# TC37XPD register map
Vendor: Infineon; Series: ATVMC; File version: 100
CPU: other r0p0, little endian, MPU, FPU, vendor SysTick, 4 interrupt priority bits
Registers are 32-bit, read-write, reset 0x0 unless marked. A register's access mark holds for its fields unless they carry their own. Offsets are from the block's base; [hi:lo] are bit positions; {n}, {i} and the like mark numbered series.

## GETH (part 4 of 7)
Base 0xF001D000
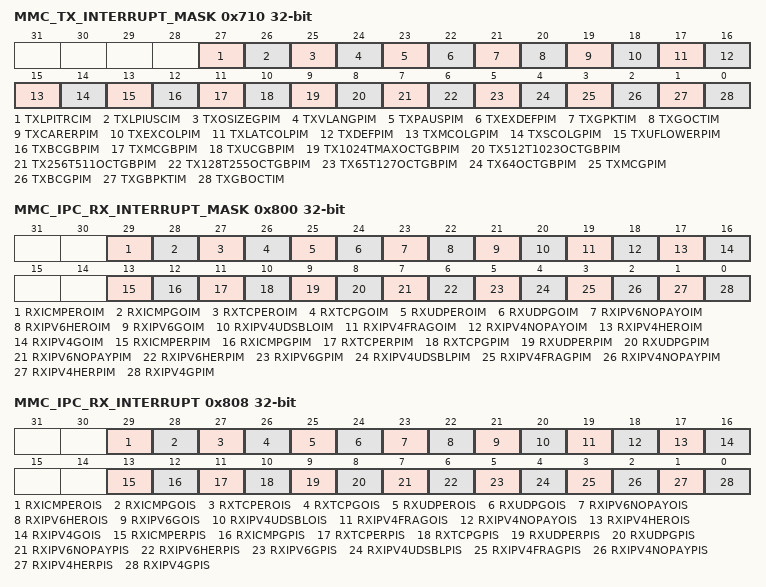
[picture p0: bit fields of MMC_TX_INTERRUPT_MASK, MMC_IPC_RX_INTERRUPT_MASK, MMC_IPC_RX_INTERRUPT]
0x710 MMC_TX_INTERRUPT_MASK — MMC Transmit Interrupts Mask Register resetvalue={Application Reset:0x0}
  [27] TXLPITRCIM — MMC Transmit LPI transition counter interrupt Mask TXLPITRCIM. Setting this bit masks the interrupt when the Tx LPI Tran Cntr counter reaches half of the maximum value or the maximum value. Value After Reset 0x0
  [26] TXLPIUSCIM — MMC Transmit LPI microsecond counter interrupt Mask TXLPIUSCIM. Setting this bit masks the interrupt when the Tx LPI USEC Cntr counter reaches half of the maximum value or the maximum value. Value After Reset 0x0
  [25] TXOSIZEGPIM — MMC Transmit Oversize Good Packet Counter Interrupt Mask TXOSIZEGPIM. Setting this bit masks the interrupt when the txoversize g counter reaches half of the maximum value or the maximum value. Value After Reset 0x0
  [24] TXVLANGPIM — MMC Transmit VLAN Good Packet Counter Interrupt Mask TXVLANGPIM. Setting this bit masks the interrupt when the txvlanpackets g counter reaches half of the maximum value or the maximum value. Value After Reset 0x0
  [23] TXPAUSPIM — MMC Transmit Pause Packet Counter Interrupt Mask TXPAUSPIM. Setting this bit masks the interrupt when the txpausepackets counter reaches half of the maximum value or the maximum value. Value After Reset 0x0
  [22] TXEXDEFPIM — MMC Transmit Excessive Deferral Packet Counter Interrupt Mask TXEXDEFPIM. Setting this bit masks the interrupt when the txexcessdef counter reaches half of the maximum value or the maximum value. Value After Reset 0x0
  [21] TXGPKTIM — MMC Transmit Good Packet Counter Interrupt Mask TXGPKTIM. Setting this bit masks the interrupt when the txpacketcount g counter reaches half of the maximum value or the maximum value. Value After Reset 0x0
  [20] TXGOCTIM — MMC Transmit Good Octet Counter Interrupt Mask TXGOCTIM. Setting this bit masks the interrupt when the txoctetcount g counter reaches half of the maximum value or the maximum value. Value After Reset 0x0
  [19] TXCARERPIM — MMC Transmit Carrier Error Packet Counter Interrupt Mask TXCARERPIM. Setting this bit masks the interrupt when the txcarriererror counter reaches half of the maximum value or the maximum value. Value After Reset 0x0
  [18] TXEXCOLPIM — MMC Transmit Excessive Collision Packet Counter Interrupt Mask TXEXCOLPIM. Setting this bit masks the interrupt when the txexcesscol counter reaches half of the maximum value or the maximum value. Value After Reset 0x0
  [17] TXLATCOLPIM — MMC Transmit Late Collision Packet Counter Interrupt Mask TXLATCOLPIM. Setting this bit masks the interrupt when the txlatecol counter reaches half of the maximum value or the maximum value. Value After Reset 0x0
  [16] TXDEFPIM — MMC Transmit Deferred Packet Counter Interrupt Mask TXDEFPIM. Setting this bit masks the interrupt when the txdeferred counter reaches half of the maximum value or the maximum value. Value After Reset 0x0
  [15] TXMCOLGPIM — MMC Transmit Multiple Collision Good Packet Counter Interrupt Mask TXMCOLGPIM. Setting this bit masks the interrupt when the txmulticol g counter reaches half of the maximum value or the maximum value. Value After Reset 0x0
  [14] TXSCOLGPIM — MMC Transmit Single Collision Good Packet Counter Interrupt Mask TXSCOLGPIM. Setting this bit masks the interrupt when the txsinglecol g counter reaches half of the maximum value or the maximum value. Value After Reset 0x0
  [13] TXUFLOWERPIM — MMC Transmit Underflow Error Packet Counter Interrupt Mask TXUFLOWERPIM. Setting this bit masks the interrupt when the txunderflowerror counter reaches half of the maximum value or the maximum value. Value After Reset 0x0
  [12] TXBCGBPIM — MMC Transmit Broadcast Good Bad Packet Counter Interrupt Mask TXBCGBPIM. Setting this bit masks the interrupt when the txbroadcastpackets gb counter reaches half of the maximum value or the maximum value. Value After Reset 0x0
  [11] TXMCGBPIM — MMC Transmit Multicast Good Bad Packet Counter Interrupt Mask TXMCGBPIM. Setting this bit masks the interrupt when the txmulticastpackets gb counter reaches half of the maximum value or the maximum value. Value After Reset 0x0
  [10] TXUCGBPIM — MMC Transmit Unicast Good Bad Packet Counter Interrupt Mask TXUCGBPIM. Setting this bit masks the interrupt when the txunicastpackets gb counter reaches half of the maximum value or the maximum value. Value After Reset 0x0
  [9] TX1024TMAXOCTGBPIM — MMC Transmit 1024 to Maximum Octet Good Bad Packet Counter Interrupt Mask TX1024TMAXOCTGBPIM. Setting this bit masks the interrupt when the tx1024tomaxoctets gb counter reaches half of the maximum value or the maximum value. Value After Reset 0x0
  [8] TX512T1023OCTGBPIM — MMC Transmit 512 to 1023 Octet Good Bad Packet Counter Interrupt Mask TX512T1023OCTGBPIM. Setting this bit masks the interrupt when the tx512to1023octets gb counter reaches half of the maximum value or the maximum value. Value After Reset 0x0
  [7] TX256T511OCTGBPIM — MMC Transmit 256 to 511 Octet Good Bad Packet Counter Interrupt Mask TX256T511OCTGBPIM. Setting this bit masks the interrupt when the tx256to511octets gb counter reaches half of the maximum value or the maximum value. Value After Reset 0x0
  [6] TX128T255OCTGBPIM — MMC Transmit 128 to 255 Octet Good Bad Packet Counter Interrupt Mask TX128T255OCTGBPIM. Setting this bit masks the interrupt when the tx128to255octets gb counter reaches half of the maximum value or the maximum value. Value After Reset 0x0
  [5] TX65T127OCTGBPIM — MMC Transmit 65 to 127 Octet Good Bad Packet Counter Interrupt Mask TX65T127OCTGBPIM. Setting this bit masks the interrupt when the tx65to127octets gb counter reaches half of the maximum value or the maximum value. Value After Reset 0x0
  [4] TX64OCTGBPIM — MMC Transmit 64 Octet Good Bad Packet Counter Interrupt Mask TX64OCTGBPIM. Setting this bit masks the interrupt when the tx64octets gb counter reaches half of the maximum value or the maximum value. Value After Reset 0x0
  [3] TXMCGPIM — MMC Transmit Multicast Good Packet Counter Interrupt Mask TXMCGPIM. Setting this bit masks the interrupt when the txmulticastpackets g counter reaches half of the maximum value or the maximum value. Value After Reset 0x0
  [2] TXBCGPIM — MMC Transmit Broadcast Good Packet Counter Interrupt Mask TXBCGPIM. Setting this bit masks the interrupt when the txbroadcastpackets g counter reaches half of the maximum value or the maximum value. Value After Reset 0x0
  [1] TXGBPKTIM — MMC Transmit Good Bad Packet Counter Interrupt Mask TXGBPKTIM. Setting this bit masks the interrupt when the txpacketcount gb counter reaches half of the maximum value or the maximum value. Value After Reset 0x0
  [0] TXGBOCTIM — MMC Transmit Good Bad Octet Counter Interrupt Mask TXGBOCTIM. Setting this bit masks the interrupt when the txoctetcount gb counter reaches half of the maximum value or the maximum value. Value After Reset 0x0
0x714 TX_OCTET_COUNT_GOOD_BAD ro — Good And Bad Transmitted Octet Count Register resetvalue={Application Reset:0x0}
  [31:0] TXOCTGB — Tx Octet Count Good Bad TXOCTGB. This field indicates the number of bytes transmitted exclusive of preamble and retried bytes in good and bad packets. Value After Reset 0x0
0x718 TX_PACKET_COUNT_GOOD_BAD ro — Good And Bad Transmitted Packets Count Register resetvalue={Application Reset:0x0}
  [15:0] TXPKTGB — Tx Packet Count Good Bad TXPKTGB. This field indicates the number of good and bad packets transmitted exclusive of retried packets. Value After Reset 0x0
0x71C TX_BROADCAST_PACKETS_GOOD ro — Good Transmitted Broadcast Packets Count Register resetvalue={Application Reset:0x0}
  [15:0] TXBCASTG — Tx Broadcast Packets Good TXBCASTG. This field indicates the number of good broadcast packets transmitted. Value After Reset 0x0
0x720 TX_MULTICAST_PACKETS_GOOD ro — Good Transmitted Multicast Packets Count Register resetvalue={Application Reset:0x0}
  [15:0] TXMCASTG — Tx Multicast Packets Good TXMCASTG. This field indicates the number of good multicast packets transmitted. Value After Reset 0x0
0x724 TX_64OCTETS_PACKETS_GOOD_BAD ro — Good And Bad 64 Octets Packets Transmitted Count Register resetvalue={Application Reset:0x0}
  [15:0] TX64OCTGB — Tx 64Octets Packets Good Bad TX64OCTGB. This field indicates the number of good and bad packets transmitted with length 64 bytes exclusive of preamble and retried packets. Value After Reset 0x0
0x728 TX_65TO127OCTETS_PACKETS_GOOD_BAD ro — Good And Bad 65to127 Octets Packets Transmitted Count Register resetvalue={Application Reset:0x0}
  [15:0] TX65_127OCTGB — Tx 65To127Octets Packets Good Bad TX65 127OCTGB. This field indicates the number of good and bad packets transmitted with length between 65 and 127 inclusive bytes exclusive of preamble and retried packets. Value After Reset 0x0
0x72C TX_128TO255OCTETS_PACKETS_GOOD_BAD ro — Good And Bad 128to255 Octets Packets Transmitted Count Register resetvalue={Application Reset:0x0}
  [15:0] TX128_255OCTGB — Tx 128To255Octets Packets Good Bad TX128 255OCTGB. This field indicates the number of good and bad packets transmitted with length between 128 and 255 inclusive bytes exclusive of preamble and retried packets. Value After Reset 0x0
0x730 TX_256TO511OCTETS_PACKETS_GOOD_BAD ro — Good And Bad 256to511 Octets Packets Transmitted Count Register resetvalue={Application Reset:0x0}
  [15:0] TX256_511OCTGB — Tx 256To511Octets Packets Good Bad TX256 511OCTGB. This field indicates the number of good and bad packets transmitted with length between 256 and 511 inclusive bytes exclusive of preamble and retried packets. Value After Reset 0x0
0x734 TX_512TO1023OCTETS_PACKETS_GOOD_BAD ro — Good And Bad 512to1023 Octets Packets Transmitted Count Register resetvalue={Application Reset:0x0}
  [15:0] TX512_1023OCTGB — Tx 512To1023Octets Packets Good Bad TX512 1023OCTGB. This field indicates the number of good and bad packets transmitted with length between 512 and 1023 inclusive bytes exclusive of preamble and retried packets. Value After Reset 0x0
0x738 TX_1024TOMAXOCTETS_PACKETS_GOOD_BAD ro — Good And Bad 1024toMax Octets Packets Transmitted Count Register resetvalue={Application Reset:0x0}
  [15:0] TX1024_MAXOCTGB — Tx 1024ToMaxOctets Packets Good Bad TX1024 MAXOCTGB. This field indicates the number of good and bad packets transmitted with length between 1024 and maxsize inclusive bytes exclusive of preamble and retried packets. Value After Reset 0x0
0x73C TX_UNICAST_PACKETS_GOOD_BAD ro — Good Transmitted Unicat Packets Count Register resetvalue={Application Reset:0x0}
  [15:0] TXUCASTGB — Tx Unicast Packets Good Bad TXUCASTGB. This field indicates the number of good and bad unicast packets transmitted. Value After Reset 0x0
0x740 TX_MULTICAST_PACKETS_GOOD_BAD ro — Good And Bad Transmitted Multicast Packets Count Register resetvalue={Application Reset:0x0}
  [15:0] TXMCASTGB — Tx Multicast Packets Good Bad TXMCASTGB. This field indicates the number of good and bad multicast packets transmitted. Value After Reset 0x0
0x744 TX_BROADCAST_PACKETS_GOOD_BAD ro — Good And Bad Transmitted Broadcast Packets Count Register resetvalue={Application Reset:0x0}
  [15:0] TXBCASTGB — Tx Broadcast Packets Good Bad TXBCASTGB. This field indicates the number of good and bad broadcast packets transmitted. Value After Reset 0x0
0x748 TX_UNDERFLOW_ERROR_PACKETS ro — Transmitted Underflow Error Packets Count Register resetvalue={Application Reset:0x0}
  [15:0] TXUNDRFLW — Tx Underflow Error Packets TXUNDRFLW. This field indicates the number of packets aborted because of packets underflow error. Value After Reset 0x0
0x74C TX_SINGLE_COLLISION_GOOD_PACKETS ro — Good Transmitted Single Collision Count Register resetvalue={Application Reset:0x0}
  [15:0] TXSNGLCOLG — Tx Single Collision Good Packets TXSNGLCOLG. This field indicates the number of successfully transmitted packets after a single collision in the half duplex mode. Value After Reset 0x0
0x750 TX_MULTIPLE_COLLISION_GOOD_PACKETS ro — Transmitted Multiple Collision Count Register resetvalue={Application Reset:0x0}
  [15:0] TXMULTCOLG — Tx Multiple Collision Good Packets TXMULTCOLG. This field indicates the number of successfully transmitted packets after multiple collisions in the half duplex mode. Value After Reset 0x0
0x754 TX_DEFERRED_PACKETS ro — Transmitted Deferred Packets Count Register resetvalue={Application Reset:0x0}
  [15:0] TXDEFRD — Tx Deferred Packets TXDEFRD. This field indicates the number of successfully transmitted after a deferral in the half duplex mode. Value After Reset 0x0
0x758 TX_LATE_COLLISION_PACKETS ro — Transmitted Late Collision Packets Count Register resetvalue={Application Reset:0x0}
  [15:0] TXLATECOL — Tx Late Collision Packets TXLATECOL. This field indicates the number of packets aborted because of late collision error. Value After Reset 0x0
0x75C TX_EXCESSIVE_COLLISION_PACKETS ro — Transmitted Excessive Collision Packets Count Register resetvalue={Application Reset:0x0}
  [15:0] TXEXSCOL — Tx Excessive Collision Packets TXEXSCOL. This field indicates the number of packets aborted because of excessive 16 collision errors. Value After Reset 0x0
0x760 TX_CARRIER_ERROR_PACKETS ro — Transmitted Carrier Error Packets Count Register resetvalue={Application Reset:0x0}
  [15:0] TXCARR — Tx Carrier Error Packets TXCARR. This field indicates the number of packets aborted because of carrier sense error no carrier or loss of carrier . Value After Reset 0x0
0x764 TX_OCTET_COUNT_GOOD ro — Good Transmitted Octet Count Register resetvalue={Application Reset:0x0}
  [31:0] TXOCTG — Tx Octet Count Good TXOCTG. This field indicates the number of bytes transmitted exclusive of preamble only in good packets. Value After Reset 0x0
0x768 TX_PACKET_COUNT_GOOD ro — Good Transmitted Packet Count Register resetvalue={Application Reset:0x0}
  [15:0] TXPKTG — Tx Packet Count Good TXPKTG. This field indicates the number of good packets transmitted. Value After Reset 0x0
0x76C TX_EXCESSIVE_DEFERRAL_ERROR ro — Transmitted Excessive Deferral Error Count Register resetvalue={Application Reset:0x0}
  [15:0] TXEXSDEF — Tx Excessive Deferral Error TXEXSDEF. This field indicates the number of packets aborted because of excessive deferral error deferred for more than two max sized packet times . Value After Reset 0x0
0x770 TX_PAUSE_PACKETS ro — Transmitted Pause Packets Count Register resetvalue={Application Reset:0x0}
  [15:0] TXPAUSE — Tx Pause Packets TXPAUSE. This field indicates the number of good Pause packets transmitted. Value After Reset 0x0
0x774 TX_VLAN_PACKETS_GOOD ro — Good Transmitted VLAN Packets Count Register resetvalue={Application Reset:0x0}
  [15:0] TXVLANG — Tx VLAN Packets Good TXVLANG. This field provides the number of good VLAN packets transmitted. Value After Reset 0x0
0x778 TX_OSIZE_PACKETS_GOOD ro — Good Transmitted Osize Packets Count Register resetvalue={Application Reset:0x0}
  [15:0] TXOSIZG — Tx OSize Packets Good TXOSIZG. This field indicates the number of packets transmitted without errors and with length greater than the maxsize 1 518 or 1 522 bytes for VLAN tagged packets 2000 bytes if enabled in S2KP bit of the MAC Configuration register . Value After Reset 0x0
0x780 RX_PACKETS_COUNT_GOOD_BAD ro — Good And Bad Received Packets Count Register resetvalue={Application Reset:0x0}
  [15:0] RXPKTGB — Rx Packets Count Good Bad RXPKTGB. This field indicates the number of good and bad packets received. Value After Reset 0x0
0x784 RX_OCTET_COUNT_GOOD_BAD ro — Good And Bad Received Octet Count Register resetvalue={Application Reset:0x0}
  [31:0] RXOCTGB — Rx Octet Count Good Bad RXOCTGB. This field indicates the number of bytes received exclusive of preamble in good and bad packets. Value After Reset 0x0
0x788 RX_OCTET_COUNT_GOOD ro — Good Received Octet Count Register resetvalue={Application Reset:0x0}
  [31:0] RXOCTG — Rx Octet Count Good RXOCTG. This field indicates the number of bytes received exclusive of preamble only in good packets. Value After Reset 0x0
0x78C RX_BROADCAST_PACKETS_GOOD ro — Good Received Broadcast Packets Count Register resetvalue={Application Reset:0x0}
  [15:0] RXBCASTG — Rx Broadcast Packets Good RXBCASTG. This field indicates the number of good broadcast packets received. Value After Reset 0x0
0x790 RX_MULTICAST_PACKETS_GOOD ro — Good Received Multicast Packets Count Register resetvalue={Application Reset:0x0}
  [15:0] RXMCASTG — Rx Multicast Packets Good RXMCASTG. This field indicates the number of good multicast packets received. Value After Reset 0x0
0x794 RX_CRC_ERROR_PACKETS ro — Received CRC Error Packets Count Register resetvalue={Application Reset:0x0}
  [15:0] RXCRCERR — Rx CRC Error Packets RXCRCERR. This field indicates the number of packets received with CRC error. Value After Reset 0x0
0x798 RX_ALIGNMENT_ERROR_PACKETS ro — Received Alignment Error Count Register resetvalue={Application Reset:0x0}
  [15:0] RXALGNERR — Rx Alignment Error Packets RXALGNERR. This field indicates the number of packets received with alignment dribble error. It is valid only in 10 100 mode. Value After Reset 0x0
0x79C RX_RUNT_ERROR_PACKETS ro — Received Runtime Error Count Register resetvalue={Application Reset:0x0}
  [15:0] RXRUNTERR — Rx Runt Error Packets RXRUNTERR. This field indicates the number of packets received with runt length less than 64 bytes and CRC error error. Value After Reset 0x0
0x7A0 RX_JABBER_ERROR_PACKETS ro — Received Jabber Error Count Register resetvalue={Application Reset:0x0}
  [15:0] RXJABERR — Rx Jabber Error Packets RXJABERR. This field indicates the number of giant packets received with length including CRC greater than 1 518 bytes 1 522 bytes for VLAN tagged and with CRC error. If Jumbo Packet mode is enabled packets of length greater than 9 018 bytes 9 022 bytes for VLAN tagged are considered as giant packets. Value After Reset 0x0
0x7A4 RX_UNDERSIZE_PACKETS_GOOD ro — Good Received Undersized Packets Count Register resetvalue={Application Reset:0x0}
  [15:0] RXUNDERSZG — Rx Undersize Packets Good RXUNDERSZG. This field indicates the number of packets received with length less than 64 bytes without any errors. Value After Reset 0x0
0x7A8 RX_OVERSIZE_PACKETS_GOOD ro — Good Received Oversized Packets Count Register resetvalue={Application Reset:0x0}
  [15:0] RXOVERSZG — Rx Oversize Packets Good RXOVERSZG. This field indicates the number of packets received without errors with length greater than the maxsize 1 518 bytes or 1 522 bytes for VLAN tagged packets 2000 bytes if enabled in the S2KP bit of the MAC Configuration register . Value After Reset 0x0
0x7AC RX_64OCTETS_PACKETS_GOOD_BAD ro — Good And Bad 64 Octets Packets Received Count Register resetvalue={Application Reset:0x0}
  [15:0] RX64OCTGB — Rx 64 Octets Packets Good Bad RX64OCTGB. This field indicates the number of good and bad packets received with length 64 bytes exclusive of the preamble. Value After Reset 0x0
0x7B0 RX_65TO127OCTETS_PACKETS_GOOD_BAD ro — Good And Bad 65to127 Octets Packets Received Count Register resetvalue={Application Reset:0x0}
  [15:0] RX65_127OCTGB — Rx 65 127 Octets Packets Good Bad RX65 127OCTGB. This field indicates the number of good and bad packets received with length between 65 and 127 inclusive bytes exclusive of the preamble. Value After Reset 0x0
0x7B4 RX_128TO255OCTETS_PACKETS_GOOD_BAD ro — Good And Bad 128to255 Octets Packets Received Count Register resetvalue={Application Reset:0x0}
  [15:0] RX128_255OCTGB — Rx 128 255 Octets Packets Good Bad RX128 255OCTGB. This field indicates the number of good and bad packets received with length between 128 and 255 inclusive bytes exclusive of the preamble. Value After Reset 0x0
0x7B8 RX_256TO511OCTETS_PACKETS_GOOD_BAD ro — Good And Bad 256to511 Octets Packets Received Count Register resetvalue={Application Reset:0x0}
  [15:0] RX256_511OCTGB — Rx 256 511 Octets Packets Good Bad RX256 511OCTGB. This field indicates the number of good and bad packets received with length between 256 and 511 inclusive bytes exclusive of the preamble. Value After Reset 0x0
0x7BC RX_512TO1023OCTETS_PACKETS_GOOD_BAD ro — Good And Bad 512to1023 Octets Packets Received Count Register resetvalue={Application Reset:0x0}
  [15:0] RX512_1023OCTGB — RX 512 1023 Octets Packets Good Bad RX512 1023OCTGB. This field indicates the number of good and bad packets received with length between 512 and 1023 inclusive bytes exclusive of the preamble. Value After Reset 0x0
0x7C0 RX_1024TOMAXOCTETS_PACKETS_GOOD_BAD ro — Good And Bad 1024toMax Octets Packets Received Count Register resetvalue={Application Reset:0x0}
  [15:0] RX1024_MAXOCTGB — Rx 1024 Max Octets Good Bad RX1024 MAXOCTGB. This field indicates the number of good and bad packets received with length between 1024 and maxsize inclusive bytes exclusive of the preamble. Value After Reset 0x0
0x7C4 RX_UNICAST_PACKETS_GOOD ro — Good Received Unicat Packets Count Register resetvalue={Application Reset:0x0}
  [15:0] RXUCASTG — Rx Unicast Packets Good RXUCASTG. This field indicates the number of good unicast packets received. Value After Reset 0x0
0x7C8 RX_LENGTH_ERROR_PACKETS ro — Received Length Error Packets Count Register resetvalue={Application Reset:0x0}
  [15:0] RXLENERR — Rx Length Error Packets RXLENERR. This field indicates the number of packets received with length error Length Type field not equal to packet size for all packets with valid length field. Value After Reset 0x0
0x7CC RX_OUT_OF_RANGE_TYPE_PACKETS ro — Received Out Of Range Type Count Register resetvalue={Application Reset:0x0}
  [15:0] RXOUTOFRNG — Rx Out of Range Type Packet RXOUTOFRNG. This field indicates the number of packets received with length field not equal to the valid packet size greater than 1 500 but less than 1 536 . Value After Reset 0x0
0x7D0 RX_PAUSE_PACKETS ro — Received Pause Packets Count Register resetvalue={Application Reset:0x0}
  [15:0] RXPAUSEPKT — Rx Pause Packets RXPAUSEPKT. This field indicates the number of good and valid Pause packets received. Value After Reset 0x0
0x7D4 RX_FIFO_OVERFLOW_PACKETS ro — Received FIFO Overflow Count Register resetvalue={Application Reset:0x0}
  [15:0] RXFIFOOVFL — Rx FIFO Overflow Packets RXFIFOOVFL. This field indicates the number of missed received packets because of FIFO overflow. Value After Reset 0x0
0x7D8 RX_VLAN_PACKETS_GOOD_BAD ro — Good And Bad Received VLAN Packets Count Registerv resetvalue={Application Reset:0x0}
  [15:0] RXVLANPKTGB — Rx VLAN Packets Good Bad RXVLANPKTGB. This field indicates the number of good and bad VLAN packets received. Value After Reset 0x0
0x7DC RX_WATCHDOG_ERROR_PACKETS ro — Received Watchdog Error Count Register resetvalue={Application Reset:0x0}
  [15:0] RXWDGERR — Rx Watchdog Error Packets RXWDGERR. This field indicates the number of packets received with error because of watchdog timeout error packets with a data load larger than 2 048 bytes when JE and WD bits are reset in MAC Configuration register 10 240 bytes when JE bit is set and WD bit is reset in MAC Configuration register 16 384 bytes when WD bit is set in MAC Configuration register or the value programmed in the MAC Watchdog Timeout register . Value After Reset 0x0
0x7E0 RX_RECEIVE_ERROR_PACKETS ro — Received Receive Error Count Register resetvalue={Application Reset:0x0}
  [15:0] RXRCVERR — Rx Receive Error Packets RXRCVERR. This field indicates the number of packets received with Receive error or Packet Extension error on the GMII or MII interface. Value After Reset 0x0
0x7E4 RX_CONTROL_PACKETS_GOOD ro — Good Received Control Packets Count Register resetvalue={Application Reset:0x0}
  [15:0] RXCTRLG — Rx Control Packets Good RXCTRLG. This field indicates the number of good control packets received. Value After Reset 0x0
0x7EC TX_LPI_USEC_CNTR ro — Transmitted LPI Microseconds Count Register resetvalue={Application Reset:0x0}
  [15:0] TXLPIUSC — Tx LPI Microseconds Counter TXLPIUSC. This field indicates the number of microseconds Tx LPI is asserted. For every Tx LPI Entry and Exit the Timer value can have an error of 1 microsecond. Value After Reset 0x0
0x7F0 TX_LPI_TRAN_CNTR ro — Transmitted LPI Transition Count Register resetvalue={Application Reset:0x0}
  [15:0] TXLPITRC — Tx LPI Transition counter TXLPITRC. This field indicates the number of times Tx LPI Entry has occurred. Even if Tx LPI Entry occurs in Automate Mode because of LPITXA bit set in the LPI Control and Status register the counter will increment. Value After Reset 0x0
0x7F4 RX_LPI_USEC_CNTR ro — Received Microseconds LPI Count Register resetvalue={Application Reset:0x0}
  [15:0] RXLPIUSC — Rx LPI Microseconds Counter RXLPIUSC. This field indicates the number of microseconds Rx LPI is asserted. For every Rx LPI Entry and Exit the Timer value can have an error of 1 microsecond. Value After Reset 0x0
0x7F8 RX_LPI_TRAN_CNTR ro — Received LPI Transition Count Register resetvalue={Application Reset:0x0}
  [15:0] RXLPITRC — Rx LPI Transition counter RXLPITRC. This field indicates the number of times Rx LPI Entry has occurred. Value After Reset 0x0
0x800 MMC_IPC_RX_INTERRUPT_MASK — MMC IPC Receive Interrupts Mask Register resetvalue={Application Reset:0x0}
  [29] RXICMPEROIM — MMC Receive ICMP Error Octet Counter Interrupt Mask RXICMPEROIM. Setting this bit masks the interrupt when the rxicmp err octets counter reaches half of the maximum value or the maximum value. Value After Reset 0x0
  [28] RXICMPGOIM — MMC Receive ICMP Good Octet Counter Interrupt Mask RXICMPGOIM. Setting this bit masks the interrupt when the rxicmp gd octets counter reaches half of the maximum value or the maximum value. Value After Reset 0x0
  [27] RXTCPEROIM — MMC Receive TCP Error Octet Counter Interrupt Mask RXTCPEROIM. Setting this bit masks the interrupt when the rxtcp err octets counter reaches half of the maximum value or the maximum value. Value After Reset 0x0
  [26] RXTCPGOIM — MMC Receive TCP Good Octet Counter Interrupt Mask RXTCPGOIM. Setting this bit masks the interrupt when the rxtcp gd octets counter reaches half of the maximum value or the maximum value. Value After Reset 0x0
  [25] RXUDPEROIM — MMC Receive UDP Good Octet Counter Interrupt Mask RXUDPEROIM. Setting this bit masks the interrupt when the rxudp err octets counter reaches half of the maximum value or the maximum value. Value After Reset 0x0
  [24] RXUDPGOIM — MMC Receive IPV6 No Payload Octet Counter Interrupt Mask RXUDPGOIM. Setting this bit masks the interrupt when the rxudp gd octets counter reaches half of the maximum value or the maximum value. Value After Reset 0x0
  [23] RXIPV6NOPAYOIM — MMC Receive IPV6 Header Error Octet Counter Interrupt Mask RXIPV6NOPAYOIM. Setting this bit masks the interrupt when the rxipv6 nopay octets counter reaches half of the maximum value or the maximum value. Value After Reset 0x0
  [22] RXIPV6HEROIM — MMC Receive IPV6 Good Octet Counter Interrupt Mask RXIPV6HEROIM. Setting this bit masks the interrupt when the rxipv6 hdrerr octets counter reaches half of the maximum value or the maximum value. Value After Reset 0x0
  [21] RXIPV6GOIM — MMC Receive IPV6 Good Octet Counter Interrupt Mask RXIPV6GOIM. Setting this bit masks the interrupt when the rxipv6 gd octets counter reaches half of the maximum value or the maximum value. Value After Reset 0x0
  [20] RXIPV4UDSBLOIM — MMC Receive IPV4 UDP Checksum Disabled Octet Counter Interrupt Mask RXIPV4UDSBLOIM. Setting this bit masks the interrupt when the rxipv4 udsbl octets counter reaches half of the maximum value or the maximum value. Value After Reset 0x0
  [19] RXIPV4FRAGOIM — MMC Receive IPV4 Fragmented Octet Counter Interrupt Mask RXIPV4FRAGOIM. Setting this bit masks the interrupt when the rxipv4 frag octets counter reaches half of the maximum value or the maximum value. Value After Reset 0x0
  [18] RXIPV4NOPAYOIM — MMC Receive IPV4 No Payload Octet Counter Interrupt Mask RXIPV4NOPAYOIM. Setting this bit masks the interrupt when the rxipv4 nopay octets counter reaches half of the maximum value or the maximum value. Value After Reset 0x0
  [17] RXIPV4HEROIM — MMC Receive IPV4 Header Error Octet Counter Interrupt Mask RXIPV4HEROIM. Setting this bit masks the interrupt when the rxipv4 hdrerr octets counter reaches half of the maximum value or the maximum value. Value After Reset 0x0
  [16] RXIPV4GOIM — MMC Receive IPV4 Good Octet Counter Interrupt Mask RXIPV4GOIM. Setting this bit masks the interrupt when the rxipv4 gd octets counter reaches half of the maximum value or the maximum value. Value After Reset 0x0
  [13] RXICMPERPIM — MMC Receive ICMP Error Packet Counter Interrupt Mask RXICMPERPIM. Setting this bit masks the interrupt when the rxicmp err pkts counter reaches half of the maximum value or the maximum value. Value After Reset 0x0
  [12] RXICMPGPIM — MMC Receive ICMP Good Packet Counter Interrupt Mask RXICMPGPIM. Setting this bit masks the interrupt when the rxicmp gd pkts counter reaches half of the maximum value or the maximum value. Value After Reset 0x0
  [11] RXTCPERPIM — MMC Receive TCP Error Packet Counter Interrupt Mask RXTCPERPIM. Setting this bit masks the interrupt when the rxtcp err pkts counter reaches half of the maximum value or the maximum value. Value After Reset 0x0
  [10] RXTCPGPIM — MMC Receive TCP Good Packet Counter Interrupt Mask RXTCPGPIM. Setting this bit masks the interrupt when the rxtcp gd pkts counter reaches half of the maximum value or the maximum value. Value After Reset 0x0
  [9] RXUDPERPIM — MMC Receive UDP Error Packet Counter Interrupt Mask RXUDPERPIM. Setting this bit masks the interrupt when the rxudp err pkts counter reaches half of the maximum value or the maximum value. Value After Reset 0x0
  [8] RXUDPGPIM — MMC Receive UDP Good Packet Counter Interrupt Mask RXUDPGPIM. Setting this bit masks the interrupt when the rxudp gd pkts counter reaches half of the maximum value or the maximum value. Value After Reset 0x0
  [7] RXIPV6NOPAYPIM — MMC Receive IPV6 No Payload Packet Counter Interrupt Mask RXIPV6NOPAYPIM. Setting this bit masks the interrupt when the rxipv6 nopay pkts counter reaches half of the maximum value or the maximum value. Value After Reset 0x0
  [6] RXIPV6HERPIM — MMC Receive IPV6 Header Error Packet Counter Interrupt Mask RXIPV6HERPIM. Setting this bit masks the interrupt when the rxipv6 hdrerr pkts counter reaches half of the maximum value or the maximum value. Value After Reset 0x0
  [5] RXIPV6GPIM — MMC Receive IPV6 Good Packet Counter Interrupt Mask RXIPV6GPIM. Setting this bit masks the interrupt when the rxipv6 gd pkts counter reaches half of the maximum value or the maximum value. Value After Reset 0x0
  [4] RXIPV4UDSBLPIM — MMC Receive IPV4 UDP Checksum Disabled Packet Counter Interrupt Mask RXIPV4UDSBLPIM. Setting this bit masks the interrupt when the rxipv4 udsbl pkts counter reaches half of the maximum value or the maximum value. Value After Reset 0x0
  [3] RXIPV4FRAGPIM — MMC Receive IPV4 Fragmented Packet Counter Interrupt Mask RXIPV4FRAGPIM. Setting this bit masks the interrupt when the rxipv4 frag pkts counter reaches half of the maximum value or the maximum value. Value After Reset 0x0
  [2] RXIPV4NOPAYPIM — MMC Receive IPV4 No Payload Packet Counter Interrupt Mask RXIPV4NOPAYPIM. Setting this bit masks the interrupt when the rxipv4 nopay pkts counter reaches half of the maximum value or the maximum value. Value After Reset 0x0
  [1] RXIPV4HERPIM — MMC Receive IPV4 Header Error Packet Counter Interrupt Mask RXIPV4HERPIM. Setting this bit masks the interrupt when the rxipv4 hdrerr pkts counter reaches half of the maximum value or the maximum value. Value After Reset 0x0
  [0] RXIPV4GPIM — MMC Receive IPV4 Good Packet Counter Interrupt Mask RXIPV4GPIM. Setting this bit masks the interrupt when the rxipv4 gd pkts counter reaches half of the maximum value or the maximum value. Value After Reset 0x0
0x808 MMC_IPC_RX_INTERRUPT ro — MMC IPC Receive Interrupts Register resetvalue={Application Reset:0x0}
  [29] RXICMPEROIS — MMC Receive ICMP Error Octet Counter Interrupt Status RXICMPEROIS. This bit is set when the rxicmp err octets counter reaches half of the maximum value or the maximum value. Access restriction applies. Clears on read. Self set to 1 on internal event. Value After Reset 0x0
  [28] RXICMPGOIS — MMC Receive ICMP Good Octet Counter Interrupt Status RXICMPGOIS. This bit is set when the rxicmp gd octets counter reaches half of the maximum value or the maximum value. Access restriction applies. Clears on read. Self set to 1 on internal event. Value After Reset 0x0
  [27] RXTCPEROIS — MMC Receive TCP Error Octet Counter Interrupt Status RXTCPEROIS. This bit is set when the rxtcp err octets counter reaches half of the maximum value or the maximum value. Access restriction applies. Clears on read. Self set to 1 on internal event. Value After Reset 0x0
  [26] RXTCPGOIS — MMC Receive TCP Good Octet Counter Interrupt Status RXTCPGOIS. This bit is set when the rxtcp gd octets counter reaches half of the maximum value or the maximum value. Access restriction applies. Clears on read. Self set to 1 on internal event. Value After Reset 0x0
  [25] RXUDPEROIS — MMC Receive UDP Error Octet Counter Interrupt Status RXUDPEROIS. This bit is set when the rxudp err octets counter reaches half of the maximum value or the maximum value. Access restriction applies. Clears on read. Self set to 1 on internal event. Value After Reset 0x0
  [24] RXUDPGOIS — MMC Receive UDP Good Octet Counter Interrupt Status RXUDPGOIS. This bit is set when the rxudp gd octets counter reaches half of the maximum value or the maximum value. Access restriction applies. Clears on read. Self set to 1 on internal event. Value After Reset 0x0
  [23] RXIPV6NOPAYOIS — MMC Receive IPV6 No Payload Octet Counter Interrupt Status RXIPV6NOPAYOIS. This bit is set when the rxipv6 nopay octets counter reaches half of the maximum value or the maximum value. Access restriction applies. Clears on read. Self set to 1 on internal event. Value After Reset 0x0
  [22] RXIPV6HEROIS — MMC Receive IPV6 Header Error Octet Counter Interrupt Status RXIPV6HEROIS. This bit is set when the rxipv6 hdrerr octets counter reaches half of the maximum value or the maximum value. Access restriction applies. Clears on read. Self set to 1 on internal event. Value After Reset 0x0
  [21] RXIPV6GOIS — MMC Receive IPV6 Good Octet Counter Interrupt Status RXIPV6GOIS. This bit is set when the rxipv6 gd octets counter reaches half of the maximum value or the maximum value. Access restriction applies. Clears on read. Self set to 1 on internal event. Value After Reset 0x0
  [20] RXIPV4UDSBLOIS — MMC Receive IPV4 UDP Checksum Disabled Octet Counter Interrupt Status RXIPV4UDSBLOIS. This bit is set when the rxipv4 udsbl octets counter reaches half of the maximum value or the maximum value. Access restriction applies. Clears on read. Self set to 1 on internal event. Value After Reset 0x0
  [19] RXIPV4FRAGOIS — MMC Receive IPV4 Fragmented Octet Counter Interrupt Status RXIPV4FRAGOIS. This bit is set when the rxipv4 frag octets counter reaches half of the maximum value or the maximum value. Access restriction applies. Clears on read. Self set to 1 on internal event. Value After Reset 0x0
  [18] RXIPV4NOPAYOIS — MMC Receive IPV4 No Payload Octet Counter Interrupt Status RXIPV4NOPAYOIS. This bit is set when the rxipv4 nopay octets counter reaches half of the maximum value or the maximum value. Access restriction applies. Clears on read. Self set to 1 on internal event. Value After Reset 0x0
  [17] RXIPV4HEROIS — MMC Receive IPV4 Header Error Octet Counter Interrupt Status RXIPV4HEROIS. This bit is set when the rxipv4 hdrerr octets counter reaches half of the maximum value or the maximum value. Access restriction applies. Clears on read. Self set to 1 on internal event. Value After Reset 0x0
  [16] RXIPV4GOIS — MMC Receive IPV4 Good Octet Counter Interrupt Status RXIPV4GOIS. This bit is set when the rxipv4 gd octets counter reaches half of the maximum value or the maximum value. Access restriction applies. Clears on read. Self set to 1 on internal event. Value After Reset 0x0
  [13] RXICMPERPIS — MMC Receive ICMP Error Packet Counter Interrupt Status RXICMPERPIS. This bit is set when the rxicmp err pkts counter reaches half of the maximum value or the maximum value. Access restriction applies. Clears on read. Self set to 1 on internal event. Value After Reset 0x0
  [12] RXICMPGPIS — MMC Receive ICMP Good Packet Counter Interrupt Status RXICMPGPIS. This bit is set when the rxicmp gd pkts counter reaches half of the maximum value or the maximum value. Access restriction applies. Clears on read. Self set to 1 on internal event. Value After Reset 0x0
  [11] RXTCPERPIS — MMC Receive TCP Error Packet Counter Interrupt Status RXTCPERPIS. This bit is set when the rxtcp err pkts counter reaches half of the maximum value or the maximum value. Access restriction applies. Clears on read. Self set to 1 on internal event. Value After Reset 0x0
  [10] RXTCPGPIS — MMC Receive TCP Good Packet Counter Interrupt Status RXTCPGPIS. This bit is set when the rxtcp gd pkts counter reaches half of the maximum value or the maximum value. Access restriction applies. Clears on read. Self set to 1 on internal event. Value After Reset 0x0
  [9] RXUDPERPIS — MMC Receive UDP Error Packet Counter Interrupt Status RXUDPERPIS. This bit is set when the rxudp err pkts counter reaches half of the maximum value or the maximum value. Access restriction applies. Clears on read. Self set to 1 on internal event. Value After Reset 0x0
  [8] RXUDPGPIS — MC Receive UDP Good Packet Counter Interrupt Status RXUDPGPIS. This bit is set when the rxudp gd pkts counter reaches half of the maximum value or the maximum value. Access restriction applies. Clears on read. Self set to 1 on internal event. Value After Reset 0x0
  [7] RXIPV6NOPAYPIS — MMC Receive IPV6 No Payload Packet Counter Interrupt Status RXIPV6NOPAYPIS. This bit is set when the rxipv6 nopay pkts counter reaches half of the maximum value or the maximum value. Access restriction applies. Clears on read. Self set to 1 on internal event. Value After Reset 0x0
  [6] RXIPV6HERPIS — MMC Receive IPV6 Header Error Packet Counter Interrupt Status RXIPV6HERPIS. This bit is set when the rxipv6 hdrerr pkts counter reaches half of the maximum value or the maximum value. Access restriction applies. Clears on read. Self set to 1 on internal event. Value After Reset 0x0
  [5] RXIPV6GPIS — MMC Receive IPV6 Good Packet Counter Interrupt Status RXIPV6GPIS. This bit is set when the rxipv6 gd pkts counter reaches half of the maximum value or the maximum value. Access restriction applies. Clears on read. Self set to 1 on internal event. Value After Reset 0x0
  [4] RXIPV4UDSBLPIS — MMC Receive IPV4 UDP Checksum Disabled Packet Counter Interrupt Status RXIPV4UDSBLPIS. This bit is set when the rxipv4 udsbl pkts counter reaches half of the maximum value or the maximum value. Value After Reset 0x0
  [3] RXIPV4FRAGPIS — MMC Receive IPV4 Fragmented Packet Counter Interrupt Status RXIPV4FRAGPIS. This bit is set when the rxipv4 frag pkts counter reaches half of the maximum value or the maximum value. Access restriction applies. Clears on read. Self set to 1 on internal event. Value After Reset 0x0
  [2] RXIPV4NOPAYPIS — MMC Receive IPV4 No Payload Packet Counter Interrupt Status RXIPV4NOPAYPIS. This bit is set when the rxipv4 nopay pkts counter reaches half of the maximum value or the maximum value. Access restriction applies. Clears on read. Self set to 1 on internal event. Value After Reset 0x0
  [1] RXIPV4HERPIS — MMC Receive IPV4 Header Error Packet Counter Interrupt Status RXIPV4HERPIS. This bit is set when the rxipv4 hdrerr pkts counter reaches half of the maximum value or the maximum value. Access restriction applies. Clears on read. Self set to 1 on internal event. Value After Reset 0x0
  [0] RXIPV4GPIS — MMC Receive IPV4 Good Packet Counter Interrupt Status RXIPV4GPIS. This bit is set when the rxipv4 gd pkts counter reaches half of the maximum value or the maximum value. Access restriction applies. Clears on read. Self set to 1 on internal event. Value After Reset 0x0
